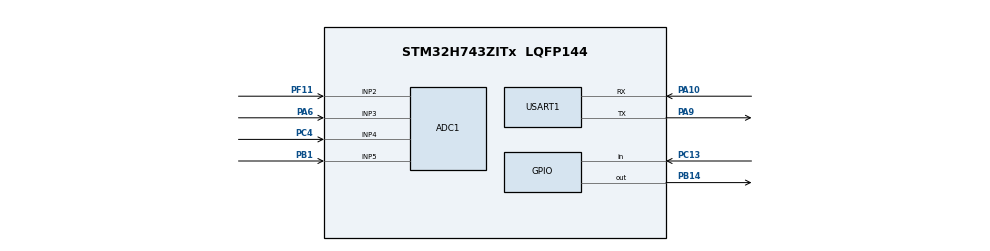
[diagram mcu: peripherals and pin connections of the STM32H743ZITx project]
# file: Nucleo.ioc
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ADC1.Channel-2\#ChannelRegularConversion=ADC_CHANNEL_2
ADC1.Channel-3\#ChannelRegularConversion=ADC_CHANNEL_3
ADC1.Channel-4\#ChannelRegularConversion=ADC_CHANNEL_4
ADC1.Channel-5\#ChannelRegularConversion=ADC_CHANNEL_5
ADC1.ExternalTrigConv=ADC_EXTERNALTRIG_T2_CC2
ADC1.NbrOfConversion=4
ADC1.NbrOfConversionFlag=1
ADC1.OffsetNumber-2\#ChannelRegularConversion=ADC_OFFSET_NONE
ADC1.OffsetNumber-3\#ChannelRegularConversion=ADC_OFFSET_NONE
ADC1.OffsetNumber-4\#ChannelRegularConversion=ADC_OFFSET_NONE
ADC1.OffsetNumber-5\#ChannelRegularConversion=ADC_OFFSET_NONE
ADC1.OffsetSignedSaturation-2\#ChannelRegularConversion=DISABLE
ADC1.OffsetSignedSaturation-3\#ChannelRegularConversion=DISABLE
ADC1.OffsetSignedSaturation-4\#ChannelRegularConversion=DISABLE
ADC1.OffsetSignedSaturation-5\#ChannelRegularConversion=DISABLE
ADC1.Rank-2\#ChannelRegularConversion=1
ADC1.Rank-3\#ChannelRegularConversion=2
ADC1.Rank-4\#ChannelRegularConversion=3
ADC1.Rank-5\#ChannelRegularConversion=4
ADC1.SamplingTime-2\#ChannelRegularConversion=ADC_SAMPLETIME_1CYCLE_5
ADC1.SamplingTime-3\#ChannelRegularConversion=ADC_SAMPLETIME_1CYCLE_5
ADC1.SamplingTime-4\#ChannelRegularConversion=ADC_SAMPLETIME_1CYCLE_5
ADC1.SamplingTime-5\#ChannelRegularConversion=ADC_SAMPLETIME_1CYCLE_5
ADC1.master=1
CORTEX_M7.default_mode_Activation=1
Mcu.Family=STM32H7
Mcu.Name=STM32H743ZITx
Mcu.Package=LQFP144
NUCLEO-H743ZI2.BUTTON=1
NUCLEO-H743ZI2.Bsp_Common_DEMO=true
NUCLEO-H743ZI2.LD1=true
NUCLEO-H743ZI2.LD2=true
NUCLEO-H743ZI2.LD3=true
NUCLEO-H743ZI2.VCP=true
NVIC.ADC_IRQn=true\:0\:0\:false\:false\:true\:true\:true\:true
NVIC.EXTI15_10_IRQn=true\:0\:0\:false\:false\:true\:false\:true\:true
NVIC.PriorityGroup=NVIC_PRIORITYGROUP_4
NVIC.TIM2_IRQn=true\:0\:0\:true\:false\:true\:true\:true\:true
NVIC.USART1_IRQn=true\:0\:0\:false\:false\:true\:true\:true\:true
PA0.Signal=S_TIM2_CH1_ETR
PA10.Mode=Asynchronous
PA10.Signal=USART1_RX
PA13\ (JTMS/SWDIO).GPIO_Label=JTMS
PA13\ (JTMS/SWDIO).Signal=DEBUG_JTMS-SWDIO
PA14\ (JTCK/SWCLK).GPIO_Label=JTCK
PA14\ (JTCK/SWCLK).Signal=DEBUG_JTCK-SWCLK
PA6.Signal=ADCx_INP3
PA9.Mode=Asynchronous
PA9.Signal=USART1_TX
PB1.Signal=ADCx_INP5
PB14.Signal=GPIO_Output
PC13.Signal=GPIO_Input
PC14-OSC32_IN\ (OSC32_IN).Signal=RCC_OSC32_IN
PC15-OSC32_OUT\ (OSC32_OUT).Signal=RCC_OSC32_OUT
PC4.Signal=ADCx_INP4
PD8.Signal=USART3_TX
PD9.Signal=USART3_RX
PF11.Mode=IN2-Single-Ended
PF11.Signal=ADC1_INP2
PH0-OSC_IN\ (PH0).Signal=RCC_OSC_IN
PH1-OSC_OUT\ (PH1).Signal=RCC_OSC_OUT
ProjectManager.HeapSize=0x200
ProjectManager.StackSize=0x400
ProjectManager.TargetToolchain=STM32CubeIDE
RCC.ADCFreq_Value=80000000
RCC.APB1Freq_Value=64000000
RCC.APB2Freq_Value=32000000
RCC.APB3Freq_Value=64000000
RCC.APB4Freq_Value=64000000
RCC.CortexFreq_Value=64000000
RCC.D2PPRE2=RCC_APB2_DIV2
RCC.DIVM2=4
RCC.DIVN2=10
RCC.HCLKFreq_Value=64000000
RCC.PLL2FRACN=0
RCC.SYSCLKFreq_VALUE=64000000
RCC.USBFreq_Value=129000000
SH.ADCx_INP3.0=ADC1_INP3,IN3-Single-Ended
SH.ADCx_INP4.0=ADC1_INP4,IN4-Single-Ended
SH.ADCx_INP5.0=ADC1_INP5,IN5-Single-Ended
SH.S_TIM2_CH1_ETR.0=TIM2_CH1
USART1.VirtualMode-Asynchronous=VM_ASYNC
VP_MEMORYMAP_VS_MEMORYMAP.Mode=CurAppReg
VP_NUCLEO-H743ZI2_VS_BSP_COMMON.Mode=COMMON
VP_TIM2_VS_ClockSourceITR.Mode=TriggerSource_ITR0
VP_TIM2_VS_ControllerModeClock.Mode=Clock Mode
board=NUCLEO-H743ZI2

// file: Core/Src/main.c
/* USER CODE BEGIN Header */
/**
  ******************************************************************************
  * @file           : main.c
  * @brief          : Main program body
  ******************************************************************************
  * @attention
  *
  * Copyright (c) 2025 STMicroelectronics.
  * All rights reserved.
  *
  * This software is licensed under terms that can be found in the LICENSE file
  * in the root directory of this software component.
  * If no LICENSE file comes with this software, it is provided AS-IS.
  *
  ******************************************************************************
  */
/* USER CODE END Header */
#include "main.h"

COM_InitTypeDef BspCOMInit;
__IO uint32_t BspButtonState = BUTTON_RELEASED;
ADC_HandleTypeDef hadc1;

TIM_HandleTypeDef htim2;

UART_HandleTypeDef huart1;

void SystemClock_Config(void);
static void MPU_Config(void);
static void MX_GPIO_Init(void);
static void MX_ADC1_Init(void);
static void MX_USART1_UART_Init(void);
static void MX_TIM2_Init(void);

int main(void)
{

  /* MPU Configuration--------------------------------------------------------*/
  MPU_Config();

  /* MCU Configuration--------------------------------------------------------*/

  /* Reset of all peripherals, Initializes the Flash interface and the Systick. */
  HAL_Init();

  /* Configure the system clock */
  SystemClock_Config();

  /* Initialize all configured peripherals */
  MX_GPIO_Init();
  MX_ADC1_Init();
  MX_USART1_UART_Init();
  MX_TIM2_Init();

  /* Initialize leds */
  BSP_LED_Init(LED_GREEN);
  BSP_LED_Init(LED_YELLOW);
  BSP_LED_Init(LED_RED);

  /* Initialize USER push-button, will be used to trigger an interrupt each time it's pressed.*/
  BSP_PB_Init(BUTTON_USER, BUTTON_MODE_EXTI);

  /* Initialize COM1 port (115200, 8 bits (7-bit data + 1 stop bit), no parity */
  BspCOMInit.BaudRate   = 115200;
  BspCOMInit.WordLength = COM_WORDLENGTH_8B;
  BspCOMInit.StopBits   = COM_STOPBITS_1;
  BspCOMInit.Parity     = COM_PARITY_NONE;
  BspCOMInit.HwFlowCtl  = COM_HWCONTROL_NONE;
  if (BSP_COM_Init(COM1, &BspCOMInit) != BSP_ERROR_NONE)
  {
    Error_Handler();
  }

  /* USER CODE BEGIN BSP */

  //HAL_ADC_Start(&hadc1);
  //HAL_ADC_Stop(&hadc1);

  printf("Welcome to STM32 world !\r\n");
  BSP_LED_On(LED_GREEN);
  BSP_LED_On(LED_YELLOW);
  BSP_LED_On(LED_RED);

  /* USER CODE END BSP */

  /* Infinite loop */
  /* USER CODE BEGIN WHILE */
  while (1)
  {

    /* -- Sample board code for User push-button in interrupt mode ---- */
    if (BspButtonState == BUTTON_PRESSED)
    {
      /* Update button state */
      BspButtonState = BUTTON_RELEASED;
      /* -- Sample board code to toggle leds ---- */
      BSP_LED_Toggle(LED_GREEN);
      BSP_LED_Toggle(LED_YELLOW);
      BSP_LED_Toggle(LED_RED);

      /* ..... Perform your action ..... */
      printf("Button pressed \r\n");
    }
    /* USER CODE END WHILE */

  }
}

void SystemClock_Config(void)
{
  RCC_OscInitTypeDef RCC_OscInitStruct = {0};
  RCC_ClkInitTypeDef RCC_ClkInitStruct = {0};

  /** Supply configuration update enable
  */
  HAL_PWREx_ConfigSupply(PWR_LDO_SUPPLY);

  /** Configure the main internal regulator output voltage
  */
  __HAL_PWR_VOLTAGESCALING_CONFIG(PWR_REGULATOR_VOLTAGE_SCALE3);

  while(!__HAL_PWR_GET_FLAG(PWR_FLAG_VOSRDY)) {}

  /** Macro to configure the PLL clock source
  */
  __HAL_RCC_PLL_PLLSOURCE_CONFIG(RCC_PLLSOURCE_HSI);

  /** Initializes the RCC Oscillators according to the specified parameters
  * in the RCC_OscInitTypeDef structure.
  */
  RCC_OscInitStruct.OscillatorType = RCC_OSCILLATORTYPE_HSI;
  RCC_OscInitStruct.HSIState = RCC_HSI_DIV1;
  RCC_OscInitStruct.HSICalibrationValue = RCC_HSICALIBRATION_DEFAULT;
  RCC_OscInitStruct.PLL.PLLState = RCC_PLL_NONE;
  if (HAL_RCC_OscConfig(&RCC_OscInitStruct) != HAL_OK)
  {
    Error_Handler();
  }

  /** Initializes the CPU, AHB and APB buses clocks
  */
  RCC_ClkInitStruct.ClockType = RCC_CLOCKTYPE_HCLK|RCC_CLOCKTYPE_SYSCLK
                              |RCC_CLOCKTYPE_PCLK1|RCC_CLOCKTYPE_PCLK2
                              |RCC_CLOCKTYPE_D3PCLK1|RCC_CLOCKTYPE_D1PCLK1;
  RCC_ClkInitStruct.SYSCLKSource = RCC_SYSCLKSOURCE_HSI;
  RCC_ClkInitStruct.SYSCLKDivider = RCC_SYSCLK_DIV1;
  RCC_ClkInitStruct.AHBCLKDivider = RCC_HCLK_DIV1;
  RCC_ClkInitStruct.APB3CLKDivider = RCC_APB3_DIV1;
  RCC_ClkInitStruct.APB1CLKDivider = RCC_APB1_DIV1;
  RCC_ClkInitStruct.APB2CLKDivider = RCC_APB2_DIV2;
  RCC_ClkInitStruct.APB4CLKDivider = RCC_APB4_DIV1;

  if (HAL_RCC_ClockConfig(&RCC_ClkInitStruct, FLASH_LATENCY_1) != HAL_OK)
  {
    Error_Handler();
  }
}

static void MX_ADC1_Init(void)
{

  ADC_MultiModeTypeDef multimode = {0};
  ADC_ChannelConfTypeDef sConfig = {0};

  /** Common config
  */
  hadc1.Instance = ADC1;
  hadc1.Init.ClockPrescaler = ADC_CLOCK_ASYNC_DIV2;
  hadc1.Init.Resolution = ADC_RESOLUTION_16B;
  hadc1.Init.ScanConvMode = ADC_SCAN_ENABLE;
  hadc1.Init.EOCSelection = ADC_EOC_SINGLE_CONV;
  hadc1.Init.LowPowerAutoWait = DISABLE;
  hadc1.Init.ContinuousConvMode = DISABLE;
  hadc1.Init.NbrOfConversion = 4;
  hadc1.Init.DiscontinuousConvMode = DISABLE;
  hadc1.Init.ExternalTrigConv = ADC_EXTERNALTRIG_T2_CC2;
  hadc1.Init.ExternalTrigConvEdge = ADC_EXTERNALTRIGCONVEDGE_RISING;
  hadc1.Init.ConversionDataManagement = ADC_CONVERSIONDATA_DR;
  hadc1.Init.Overrun = ADC_OVR_DATA_PRESERVED;
  hadc1.Init.LeftBitShift = ADC_LEFTBITSHIFT_NONE;
  hadc1.Init.OversamplingMode = DISABLE;
  hadc1.Init.Oversampling.Ratio = 1;
  if (HAL_ADC_Init(&hadc1) != HAL_OK)
  {
    Error_Handler();
  }

  /** Configure the ADC multi-mode
  */
  multimode.Mode = ADC_MODE_INDEPENDENT;
  if (HAL_ADCEx_MultiModeConfigChannel(&hadc1, &multimode) != HAL_OK)
  {
    Error_Handler();
  }

  /** Configure Regular Channel
  */
  sConfig.Channel = ADC_CHANNEL_2;
  sConfig.Rank = ADC_REGULAR_RANK_1;
  sConfig.SamplingTime = ADC_SAMPLETIME_1CYCLE_5;
  sConfig.SingleDiff = ADC_SINGLE_ENDED;
  sConfig.OffsetNumber = ADC_OFFSET_NONE;
  sConfig.Offset = 0;
  sConfig.OffsetSignedSaturation = DISABLE;
  if (HAL_ADC_ConfigChannel(&hadc1, &sConfig) != HAL_OK)
  {
    Error_Handler();
  }

  /** Configure Regular Channel
  */
  sConfig.Channel = ADC_CHANNEL_3;
  sConfig.Rank = ADC_REGULAR_RANK_2;
  if (HAL_ADC_ConfigChannel(&hadc1, &sConfig) != HAL_OK)
  {
    Error_Handler();
  }

  /** Configure Regular Channel
  */
  sConfig.Channel = ADC_CHANNEL_4;
  sConfig.Rank = ADC_REGULAR_RANK_3;
  if (HAL_ADC_ConfigChannel(&hadc1, &sConfig) != HAL_OK)
  {
    Error_Handler();
  }

  /** Configure Regular Channel
  */
  sConfig.Channel = ADC_CHANNEL_5;
  sConfig.Rank = ADC_REGULAR_RANK_4;
  if (HAL_ADC_ConfigChannel(&hadc1, &sConfig) != HAL_OK)
  {
    Error_Handler();
  }

}

static void MX_TIM2_Init(void)
{

  TIM_SlaveConfigTypeDef sSlaveConfig = {0};
  TIM_MasterConfigTypeDef sMasterConfig = {0};

  htim2.Instance = TIM2;
  htim2.Init.Prescaler = 0;
  htim2.Init.CounterMode = TIM_COUNTERMODE_UP;
  htim2.Init.Period = 4294967295;
  htim2.Init.ClockDivision = TIM_CLOCKDIVISION_DIV1;
  htim2.Init.AutoReloadPreload = TIM_AUTORELOAD_PRELOAD_DISABLE;
  if (HAL_TIM_Base_Init(&htim2) != HAL_OK)
  {
    Error_Handler();
  }
  sSlaveConfig.SlaveMode = TIM_SLAVEMODE_EXTERNAL1;
  sSlaveConfig.InputTrigger = TIM_TS_ITR0;
  if (HAL_TIM_SlaveConfigSynchro(&htim2, &sSlaveConfig) != HAL_OK)
  {
    Error_Handler();
  }
  sMasterConfig.MasterOutputTrigger = TIM_TRGO_RESET;
  sMasterConfig.MasterSlaveMode = TIM_MASTERSLAVEMODE_DISABLE;
  if (HAL_TIMEx_MasterConfigSynchronization(&htim2, &sMasterConfig) != HAL_OK)
  {
    Error_Handler();
  }

}

static void MX_USART1_UART_Init(void)
{

  huart1.Instance = USART1;
  huart1.Init.BaudRate = 115200;
  huart1.Init.WordLength = UART_WORDLENGTH_8B;
  huart1.Init.StopBits = UART_STOPBITS_1;
  huart1.Init.Parity = UART_PARITY_NONE;
  huart1.Init.Mode = UART_MODE_TX_RX;
  huart1.Init.HwFlowCtl = UART_HWCONTROL_NONE;
  huart1.Init.OverSampling = UART_OVERSAMPLING_16;
  huart1.Init.OneBitSampling = UART_ONE_BIT_SAMPLE_DISABLE;
  huart1.Init.ClockPrescaler = UART_PRESCALER_DIV1;
  huart1.AdvancedInit.AdvFeatureInit = UART_ADVFEATURE_NO_INIT;
  if (HAL_UART_Init(&huart1) != HAL_OK)
  {
    Error_Handler();
  }
  if (HAL_UARTEx_SetTxFifoThreshold(&huart1, UART_TXFIFO_THRESHOLD_1_8) != HAL_OK)
  {
    Error_Handler();
  }
  if (HAL_UARTEx_SetRxFifoThreshold(&huart1, UART_RXFIFO_THRESHOLD_1_8) != HAL_OK)
  {
    Error_Handler();
  }
  if (HAL_UARTEx_DisableFifoMode(&huart1) != HAL_OK)
  {
    Error_Handler();
  }

}

static void MX_GPIO_Init(void)
{

  /* GPIO Ports Clock Enable */
  __HAL_RCC_GPIOC_CLK_ENABLE();
  __HAL_RCC_GPIOH_CLK_ENABLE();
  __HAL_RCC_GPIOA_CLK_ENABLE();
  __HAL_RCC_GPIOB_CLK_ENABLE();
  __HAL_RCC_GPIOF_CLK_ENABLE();

}

 /* MPU Configuration */

void MPU_Config(void)
{
  MPU_Region_InitTypeDef MPU_InitStruct = {0};

  /* Disables the MPU */
  HAL_MPU_Disable();

  /** Initializes and configures the Region and the memory to be protected
  */
  MPU_InitStruct.Enable = MPU_REGION_ENABLE;
  MPU_InitStruct.Number = MPU_REGION_NUMBER0;
  MPU_InitStruct.BaseAddress = 0x0;
  MPU_InitStruct.Size = MPU_REGION_SIZE_4GB;
  MPU_InitStruct.SubRegionDisable = 0x87;
  MPU_InitStruct.TypeExtField = MPU_TEX_LEVEL0;
  MPU_InitStruct.AccessPermission = MPU_REGION_NO_ACCESS;
  MPU_InitStruct.DisableExec = MPU_INSTRUCTION_ACCESS_DISABLE;
  MPU_InitStruct.IsShareable = MPU_ACCESS_SHAREABLE;
  MPU_InitStruct.IsCacheable = MPU_ACCESS_NOT_CACHEABLE;
  MPU_InitStruct.IsBufferable = MPU_ACCESS_NOT_BUFFERABLE;

  HAL_MPU_ConfigRegion(&MPU_InitStruct);
  /* Enables the MPU */
  HAL_MPU_Enable(MPU_PRIVILEGED_DEFAULT);

}

/**
  * @brief BSP Push Button callback
  * @param Button Specifies the pressed button
  * @retval None
  */
void BSP_PB_Callback(Button_TypeDef Button)
{
  if (Button == BUTTON_USER)
  {
    BspButtonState = BUTTON_PRESSED;
  }
}

void Error_Handler(void)
{
  __disable_irq();
  while (1)
  {
  }
}
